# ATmega328PB device description
Architecture: AVR8; Family: megaAVR
Registers are 8-bit, access not given, no defined reset value unless marked. A register's access mark holds for its fields unless they carry their own. Offsets are from the block's base; [hi:lo] are bit positions; 'fields as' and 'values as' point back to an identical list.

## SPI0
Instances: SPI0 0x00
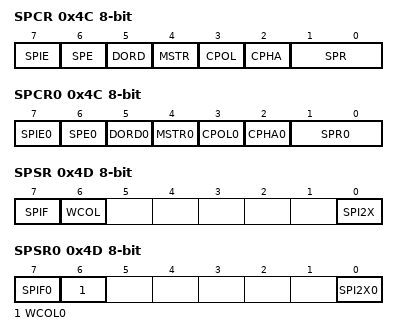
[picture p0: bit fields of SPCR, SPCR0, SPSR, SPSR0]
0x4C SPCR — SPI Control Register
  [7] SPIE — SPI Interrupt Enable
  [6] SPE — SPI Enable
  [5] DORD — Data Order
  [4] MSTR — Master/Slave Select
  [3] CPOL — Clock polarity
  [2] CPHA — Clock Phase
  [1:0] SPR — SPI Clock Rate Selects
    0=FOSC_2_OR_FOSC_4; 1=FOSC_8_OR_FOSC_16; 2=FOSC_32_OR_FOSC_64; 3=FOSC_64_OR_FOSC_128
0x4C SPCR0 — SPI Control Register
  [7] SPIE0 — SPI Interrupt Enable
  [6] SPE0 — SPI Enable
  [5] DORD0 — Data Order
  [4] MSTR0 — Master/Slave Select
  [3] CPOL0 — Clock polarity
  [2] CPHA0 — Clock Phase
  [1:0] SPR0 — SPI Clock Rate Selects
    values as SPCR.SPR
0x4D SPSR — SPI Status Register
  [7] SPIF — SPI Interrupt Flag
  [6] WCOL — Write Collision Flag
  [0] SPI2X — Double SPI Speed Bit
0x4D SPSR0 — SPI Status Register
  [7] SPIF0 — SPI Interrupt Flag
  [6] WCOL0 — Write Collision Flag
  [0] SPI2X0 — Double SPI Speed Bit
0x4E SPDR0 — SPI Data Register

## SPI1
Instances: SPI1 0x00
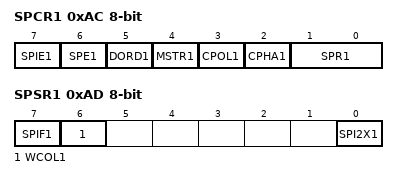
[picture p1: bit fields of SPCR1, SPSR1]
0xAC SPCR1 — SPI Control Register
  [7] SPIE1 — SPI Interrupt Enable
  [6] SPE1 — SPI Enable
  [5] DORD1 — Data Order
  [4] MSTR1 — Master/Slave Select
  [3] CPOL1 — Clock polarity
  [2] CPHA1 — Clock Phase
  [1:0] SPR1 — SPI Clock Rate Selects
    0=FOSC_2_OR_FOSC_4; 1=FOSC_8_OR_FOSC_16; 2=FOSC_32_OR_FOSC_64; 3=FOSC_64_OR_FOSC_128
0xAD SPSR1 — SPI Status Register
  [7] SPIF1 — SPI Interrupt Flag
  [6] WCOL1 — Write Collision Flag
  [0] SPI2X1 — Double SPI Speed Bit
0xAE SPDR1 — SPI Data Register

## WDT
Instances: WDT 0x00
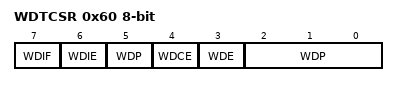
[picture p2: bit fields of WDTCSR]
0x60 WDTCSR — Watchdog Timer Control Register
  [7] WDIF — Watchdog Timeout Interrupt Flag
  [6] WDIE — Watchdog Timeout Interrupt Enable
  [4] WDCE — Watchdog Change Enable
  [3] WDE — Watch Dog Enable
  [5,2:0] WDP — Watchdog Timer Prescaler Bits
    0=OSCILLATOR_CYCLES_2K; 1=OSCILLATOR_CYCLES_4K; 2=OSCILLATOR_CYCLES_8K; 3=OSCILLATOR_CYCLES_16K; 4=OSCILLATOR_CYCLES_32K; 5=OSCILLATOR_CYCLES_64K; 6=OSCILLATOR_CYCLES_128K; 7=OSCILLATOR_CYCLES_256K; 8=OSCILLATOR_CYCLES_512K; 9=OSCILLATOR_CYCLES_1024K

## CFD
Instances: CFD 0x00
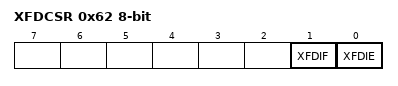
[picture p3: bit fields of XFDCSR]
0x62 XFDCSR — XOSC Failure Detection Control and Status Register
  [1] XFDIF — Failure Detection Interrupt Flag
  [0] XFDIE — Failure Detection Interrupt Enable

## CPU
Instances: CPU 0x00
0x3E GPIOR0 — General Purpose I/O Register 0
0x4A GPIOR1 — General Purpose I/O Register 1
0x4B GPIOR2 — General Purpose I/O Register 2
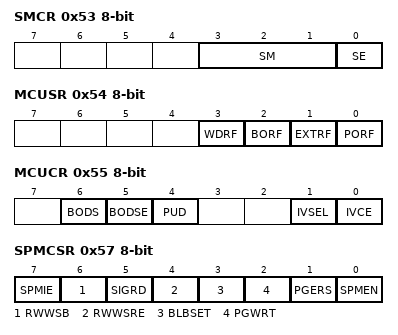
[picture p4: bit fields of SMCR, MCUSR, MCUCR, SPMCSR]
0x53 SMCR — Sleep Mode Control Register
  [3:1] SM — Sleep Mode Select Bits
    0=IDLE; 1=ADC (ADC Noise Reduction (If Available)); 2=PDOWN (Power Down); 3=PSAVE (Power Save); 6=STDBY (Standby); 7=ESTDBY (Extended Standby)
  [0] SE — Sleep Enable
0x54 MCUSR — MCU Status Register
  [3] WDRF — Watchdog Reset Flag
  [2] BORF — Brown-out Reset Flag
  [1] EXTRF — External Reset Flag
  [0] PORF — Power-on reset flag
0x55 MCUCR — MCU Control Register
  [6] BODS — BOD Sleep
  [5] BODSE — BOD Sleep Enable
  [4] PUD
  [1] IVSEL
  [0] IVCE
0x57 SPMCSR — Store Program Memory Control and Status Register
  [7] SPMIE — SPM Interrupt Enable
  [6] RWWSB — Read-While-Write Section Busy
  [5] SIGRD — Signature Row Read
  [4] RWWSRE — Read-While-Write section read enable
  [3] BLBSET — Boot Lock Bit Set
  [2] PGWRT — Page Write
  [1] PGERS — Page Erase
  [0] SPMEN — Store Program Memory
0x5D SP 16-bit bits used 11:0 — Stack Pointer
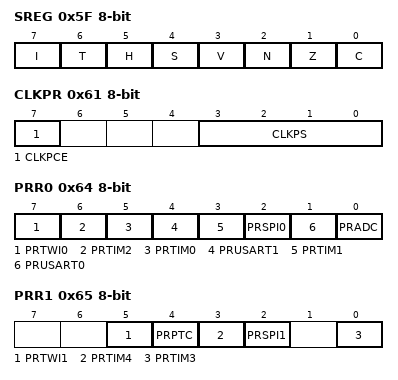
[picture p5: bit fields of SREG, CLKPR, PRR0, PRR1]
0x5F SREG — Status Register
  [7] I — Global Interrupt Enable
  [6] T — Bit Copy Storage
  [5] H — Half Carry Flag
  [4] S — Sign Bit
  [3] V — Two's Complement Overflow Flag
  [2] N — Negative Flag
  [1] Z — Zero Flag
  [0] C — Carry Flag
0x61 CLKPR — Clock Prescale Register
  [7] CLKPCE — Clock Prescaler Change Enable
  [3:0] CLKPS — Clock Prescaler Select Bits
    0=1; 1=2; 2=4; 3=8; 4=16; 5=32; 6=64; 7=128; 8=256
0x64 PRR0 — Power Reduction Register 0
  [7] PRTWI0 — Power Reduction TWI0
  [6] PRTIM2 — Power Reduction Timer/Counter2
  [5] PRTIM0 — Power Reduction Timer/Counter0
  [4] PRUSART1 — Power Reduction USART1
  [3] PRTIM1 — Power Reduction Timer/Counter1
  [2] PRSPI0 — Power Reduction Serial Peripheral Interface 1
  [1] PRUSART0 — Power Reduction USART0
  [0] PRADC — Power Reduction ADC
0x65 PRR1 — Power Reduction Register 1
  [5] PRTWI1 — Power Reduction TWI1
  [4] PRPTC — Power Reduction Peripheral Touch Controller
  [3] PRTIM4 — Power Reduction Timer/Counter4
  [2] PRSPI1 — Power Reduction Serial Peripheral Interface 1
  [0] PRTIM3 — Power Reduction Timer/Counter3
0x66 OSCCAL — Oscillator Calibration Value
  [7:0] OSCCAL — Oscillator Calibration
Value list OSCCAL_VALUE_ADDRESSES: 0=8_0_MHz

## EEPROM
Instances: EEPROM 0x00
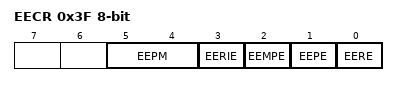
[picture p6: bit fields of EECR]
0x3F EECR — EEPROM Control Register
  [5:4] EEPM — EEPROM Programming Mode Bits
    0=ERASE_AND_WRITE_IN_ONE_OPERATION; 1=ERASE_ONLY; 2=WRITE_ONLY
  [3] EERIE — EEPROM Ready Interrupt Enable
  [2] EEMPE — EEPROM Master Write Enable
  [1] EEPE — EEPROM Write Enable
  [0] EERE — EEPROM Read Enable
0x40 EEDR — EEPROM Data Register
0x41 EEAR 16-bit bits used 9:0 — EEPROM Address Register Bytes
